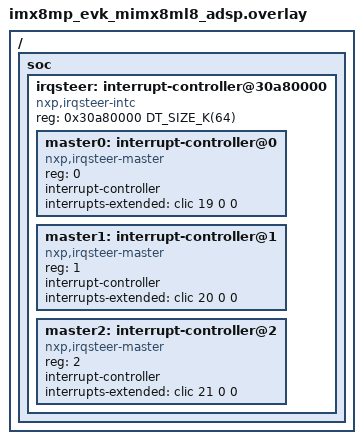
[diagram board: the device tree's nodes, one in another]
/*
 * Copyright (c) 2024 Meta
 *
 * SPDX-License-Identifier: Apache-2.0
 */

/*
 * Made-up devicetree to build intc_nxp_irqsteer.c, refer to:
 * https://github.com/zephyrproject-rtos/zephyr/pull/62776#issuecomment-1727846332
 */

 /{
	soc {
		irqsteer: interrupt-controller@30a80000 {
			compatible = "nxp,irqsteer-intc";
			reg = <0x30a80000 DT_SIZE_K(64)>;

			#size-cells = <0>;
			#address-cells = <1>;

			master0: interrupt-controller@0 {
			    compatible = "nxp,irqsteer-master";
			    reg = <0>;
			    interrupt-controller;
			    #interrupt-cells = <1>;
			    interrupts-extended = <&clic 19 0 0>;
			};

			master1: interrupt-controller@1 {
				compatible = "nxp,irqsteer-master";
				reg = <1>;
				interrupt-controller;
				#interrupt-cells = <1>;
				interrupts-extended = <&clic 20 0 0>;
			};

			master2: interrupt-controller@2 {
				compatible = "nxp,irqsteer-master";
				reg = <2>;
				interrupt-controller;
				#interrupt-cells = <1>;
				interrupts-extended = <&clic 21 0 0>;
			};
		};
	};
};
